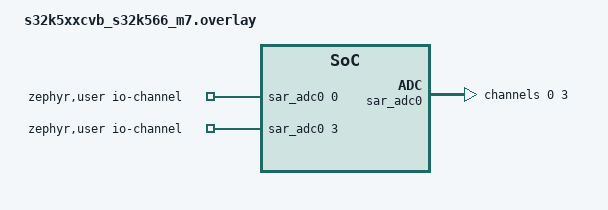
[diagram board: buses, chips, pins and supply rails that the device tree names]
/*
 * Copyright 2025 NXP
 *
 * SPDX-License-Identifier: Apache-2.0
 */

#include <zephyr/dt-bindings/adc/adc.h>

/ {
	zephyr,user {
		io-channels = <&sar_adc0 0>, <&sar_adc0 3>;
	};
};

&sar_adc0 {
	group-channel = "precision";
	status = "okay";
	#address-cells = <1>;
	#size-cells = <0>;

	channel@0 {
		reg = <0>;
		zephyr,gain = "ADC_GAIN_1";
		zephyr,reference = "ADC_REF_INTERNAL";
		zephyr,acquisition-time = <ADC_ACQ_TIME_DEFAULT>;
		zephyr,resolution = <11>;
	};

	channel@3 {
		reg = <3>;
		zephyr,gain = "ADC_GAIN_1";
		zephyr,reference = "ADC_REF_INTERNAL";
		zephyr,acquisition-time = <ADC_ACQ_TIME_DEFAULT>;
		zephyr,resolution = <11>;
	};
};
